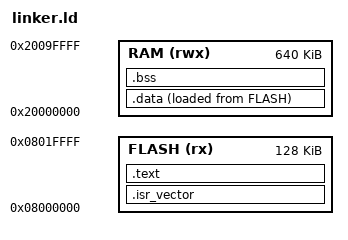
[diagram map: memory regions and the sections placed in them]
/* Bootloader linker script - lives at 0x08000000, the real reset address.
   Occupies the 128 KB before the application (which starts at 0x08020000). */
ENTRY(Reset_Handler)

MEMORY
{
  FLASH (rx)  : ORIGIN = 0x08000000, LENGTH = 128K
  RAM   (rwx) : ORIGIN = 0x20000000, LENGTH = 640K
}

_estack = ORIGIN(RAM) + LENGTH(RAM);

SECTIONS
{
  .isr_vector :
  {
    . = ALIGN(4);
    KEEP(*(.isr_vector))
    . = ALIGN(4);
  } >FLASH

  .text :
  {
    . = ALIGN(4);
    *(.text*)
    *(.rodata*)
    . = ALIGN(4);
    _etext = .;
  } >FLASH

  _sidata = LOADADDR(.data);

  .data :
  {
    . = ALIGN(4);
    _sdata = .;
    *(.data*)
    . = ALIGN(4);
    _edata = .;
  } >RAM AT> FLASH

  .bss :
  {
    . = ALIGN(4);
    _sbss = .;
    *(.bss*)
    *(COMMON)
    . = ALIGN(4);
    _ebss = .;
  } >RAM

  /* end of used RAM - heap starts here (newlib's _sbrk needs 'end') */
  . = ALIGN(4);
  end = .;
  _end = .;
  PROVIDE(end = .);
}
